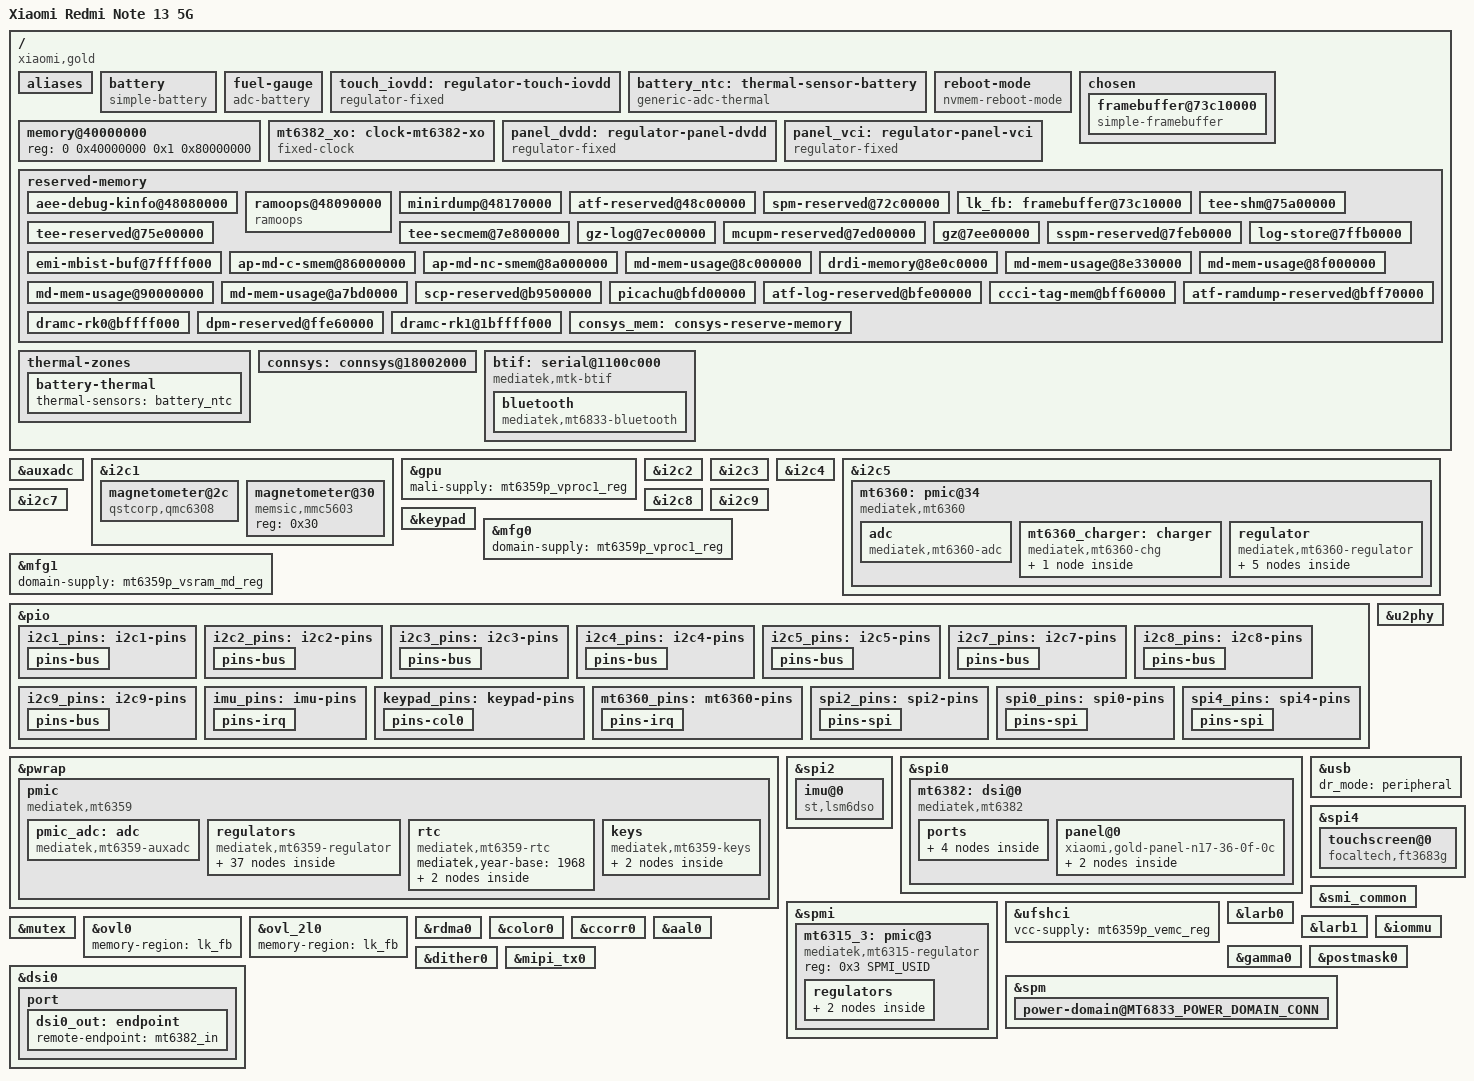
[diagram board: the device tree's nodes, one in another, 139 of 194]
// SPDX-License-Identifier: (GPL-2.0-only OR MIT)
/*
 * Xiaomi Redmi Note 13 5G (gold)
 */

/dts-v1/;
#include <dt-bindings/gpio/gpio.h>
#include <dt-bindings/iio/adc/mediatek,mt6359-auxadc.h>
#include <dt-bindings/input/input.h>
#include <dt-bindings/interrupt-controller/irq.h>
#include <dt-bindings/pinctrl/mt6833-pinfunc.h>
#include <dt-bindings/regulator/mediatek,mt6360-regulator.h>
#include <dt-bindings/spmi/spmi.h>
#include "mt6833.dtsi"

/ {
	model = "Xiaomi Redmi Note 13 5G";
	compatible = "xiaomi,gold", "mediatek,mt6833";
	chassis-type = "handset";

	aliases {
		i2c1 = &i2c1;
		i2c2 = &i2c2;
		i2c3 = &i2c3;
		i2c4 = &i2c4;
		i2c5 = &i2c5;
		i2c7 = &i2c7;
		i2c8 = &i2c8;
		i2c9 = &i2c9;
	};

	/*
	 * As the stock kernel charges it through the MT6360 alone at 15-47 C, before the cycle
	 * count lowers the voltage: up to 4.46 V (4.47-4.48 V only below 15 C), at 2 A (2.05 A
	 * for wall chargers), ending at 250 mA.
	 */
	battery: battery {
		compatible = "simple-battery";
		constant-charge-voltage-max-microvolt = <4460000>;
		constant-charge-current-max-microamp = <2000000>;
		charge-term-current-microamp = <250000>;

		/*
		 * The stock JEITA steps for chargers other than PPS, in whole degrees: no
		 * charging at -10 C and below or at 58 C and above; 490 mA at -9 to 0 C (980 mA
		 * at 1 to 5 C: taken as 490 mA here, which the MT6360 sets as 400 mA); 2.45-3.6 A
		 * at 6-47 C, more than the MT6360 alone gives; at 48-57 C only up to 4.1 V.
		 */
		operating-range-celsius = <(-9) 57>;
		alert-celsius = <6 47>;
		alert-low-temp-charge-current-microamp = <490000>;
		alert-high-temp-charge-voltage-microvolt = <4100000>;

		/*
		 * The stock gauge's profile for the first of the two cells it knows (battery0, the
		 * one it takes when the authentication chip names neither) at 25 C: OCV by depth of
		 * discharge down to 2.88 V (5104 mAh), and the median of its discharge resistance
		 * from 10 to 90 %. The stock kernel reports a design capacity of 5000 mAh.
		 */
		charge-full-design-microamp-hours = <5000000>;
		factory-internal-resistance-micro-ohms = <54000>;
		ocv-capacity-celsius = <25>;
		ocv-capacity-table-0 = <4445000 100>, <4379000 95>, <4321000 90>, <4260000 85>,
				       <4196000 80>, <4134000 75>, <4077000 70>, <4024000 65>,
				       <3976000 60>, <3919000 55>, <3871000 50>, <3842000 45>,
				       <3818000 40>, <3800000 35>, <3784000 30>, <3761000 25>,
				       <3740000 20>, <3712000 15>, <3687000 10>, <3623000 5>,
				       <3569000 4>, <3498000 3>, <3397000 2>, <3232000 1>,
				       <2880000 0>;
	};

	/*
	 * The MT6359P measures the battery voltage, and its fuel gauge the current through the
	 * 5 mOhm sense resistor, positive while charging.
	 */
	fuel-gauge {
		compatible = "adc-battery";
		io-channels = <&pmic_adc MT6359_AUXADC_BATADC>,
			      <&pmic_adc MT6359_AUXADC_IBAT>,
			      <&battery_ntc>;
		io-channel-names = "voltage", "current", "temperature";
		monitored-battery = <&battery>;
		power-supplies = <&mt6360_charger>;
	};

	/* the touchscreen's I/O supply, switched by a GPIO; on at handover */
	touch_iovdd: regulator-touch-iovdd {
		compatible = "regulator-fixed";
		regulator-name = "touch_iovdd";
		regulator-min-microvolt = <1800000>;
		regulator-max-microvolt = <1800000>;
		gpio = <&pio 138 GPIO_ACTIVE_HIGH>;
		enable-active-high;
		regulator-boot-on;
	};

	/*
	 * The battery's NTC thermistor, a Murata NCP15XH103 (10 kOhm, B 3380 K) as the stock
	 * kernel's table has it, on the MT6359P's BATON pin, pulled up to VBIF28 (2.8 V) through
	 * 24 kOhm. Its voltage in mV, 2800 * R / (R + 24000), by temperature in millicelsius.
	 */
	battery_ntc: thermal-sensor-battery {
		compatible = "generic-adc-thermal";
		#thermal-sensor-cells = <0>;
		#io-channel-cells = <0>;
		io-channels = <&pmic_adc MT6359_AUXADC_BAT_TEMP>;
		io-channel-names = "sensor-channel";
		temperature-lookup-table = <
			(-40000) 2494  (-35000) 2410  (-30000) 2311  (-25000) 2198
			(-20000) 2071  (-15000) 1935  (-10000) 1790   (-5000) 1639
			      0  1488     5000  1340    10000  1197    15000  1062
			  20000   938    25000   824    30000   720    35000   629
			  40000   548    45000   476    50000   414    55000   359
			  60000   312    65000   272    70000   238    75000   208
			  80000   182    85000   160    90000   141    95000   124
			 100000   109   105000    97   110000    86   115000    76
			 120000    68   125000    61
		>;
	};

	reboot-mode {
		compatible = "nvmem-reboot-mode";
		nvmem-cells = <&rtc_fastboot>;
		nvmem-cell-names = "reboot-mode";
		mode-bootloader = <1>;
	};

	chosen {
		#address-cells = <2>;
		#size-cells = <2>;
		ranges;

		bootargs = "console=tty0 loglevel=7 panic=10 clk_ignore_unused";

		/* The bootloader leaves the panel lit, scanning out this buffer */
		framebuffer@73c10000 {
			compatible = "simple-framebuffer";
			reg = <0 0x73c10000 0 (4352 * 2400)>;
			width = <1080>;
			height = <2400>;
			stride = <4352>;
			format = "a8r8g8b8";
		};
	};

	memory@40000000 {
		device_type = "memory";
		reg = <0 0x40000000 0x1 0x80000000>;
	};

	/*
	 * The MT6359P clock buffer output (XO_NFC) the MT6382 runs from, and
	 * passes on to an NFC controller as its own clock output. The
	 * bootloader turns it on; there is no clock buffer driver yet, so it is
	 * described as always running.
	 */
	mt6382_xo: clock-mt6382-xo {
		compatible = "fixed-clock";
		#clock-cells = <0>;
		clock-frequency = <26000000>;
		clock-output-names = "xo_nfc";
	};

	/* The panel supplies behind GPIO131 and GPIO137, left on by the bootloader */
	panel_dvdd: regulator-panel-dvdd {
		compatible = "regulator-fixed";
		regulator-name = "panel_dvdd";
		gpio = <&pio 131 GPIO_ACTIVE_HIGH>;
		enable-active-high;
		regulator-boot-on;
		startup-delay-us = <11000>;
	};

	/* never switched off by the stock kernel either */
	panel_vci: regulator-panel-vci {
		compatible = "regulator-fixed";
		regulator-name = "panel_vci";
		gpio = <&pio 137 GPIO_ACTIVE_HIGH>;
		enable-active-high;
		regulator-boot-on;
		regulator-always-on;
	};

	/*
	 * The regions the bootloader reserves for the firmware it starts (ATF, TEE, GenieZone, the
	 * SSPM, MCUPM and SCP coprocessors, the modem) and for itself, as it reports them.
	 */
	reserved-memory {
		#address-cells = <2>;
		#size-cells = <2>;
		ranges;

		aee-debug-kinfo@48080000 {
			reg = <0x0 0x48080000 0 0x10000>;
			no-map;
		};

		ramoops@48090000 {
			compatible = "ramoops";
			reg = <0x0 0x48090000 0 0xe0000>;
			console-size = <0x40000>;
			pmsg-size = <0x80000>;
			no-map;
		};

		minirdump@48170000 {
			reg = <0x0 0x48170000 0 0x10000>;
			no-map;
		};

		atf-reserved@48c00000 {
			reg = <0x0 0x48c00000 0 0x200000>;
			no-map;
		};

		spm-reserved@72c00000 {
			reg = <0x0 0x72c00000 0 0x10000>;
			no-map;
		};

		/*
		 * The bootloader's framebuffer, which the display keeps scanning
		 * out when its driver takes over: 1:1 in the display's IOMMU
		 * domain, so that it stays valid when the larb ports switch from
		 * physical addresses to the M4U.
		 */
		lk_fb: framebuffer@73c10000 {
			reg = <0x0 0x73c10000 0 0x1df0000>;
			iommu-addresses = <&ovl0 0x0 0x73c10000 0x0 0x1df0000>,
					  <&ovl_2l0 0x0 0x73c10000 0x0 0x1df0000>;
			no-map;
		};

		tee-shm@75a00000 {
			reg = <0x0 0x75a00000 0 0x400000>;
			no-map;
		};

		tee-reserved@75e00000 {
			reg = <0x0 0x75e00000 0 0x8a00000>;
			no-map;
		};

		tee-secmem@7e800000 {
			reg = <0x0 0x7e800000 0 0x400000>;
			no-map;
		};

		gz-log@7ec00000 {
			reg = <0x0 0x7ec00000 0 0x41000>;
			no-map;
		};

		mcupm-reserved@7ed00000 {
			reg = <0x0 0x7ed00000 0 0x100000>;
			no-map;
		};

		gz@7ee00000 {
			reg = <0x0 0x7ee00000 0 0x1000000>;
			no-map;
		};

		sspm-reserved@7feb0000 {
			reg = <0x0 0x7feb0000 0 0x100000>;
			no-map;
		};

		log-store@7ffb0000 {
			reg = <0x0 0x7ffb0000 0 0x40000>;
			no-map;
		};

		emi-mbist-buf@7ffff000 {
			reg = <0x0 0x7ffff000 0 0x1000>;
			no-map;
		};

		ap-md-c-smem@86000000 {
			reg = <0x0 0x86000000 0 0x2960000>;
			no-map;
		};

		ap-md-nc-smem@8a000000 {
			reg = <0x0 0x8a000000 0 0x1b0000>;
			no-map;
		};

		md-mem-usage@8c000000 {
			reg = <0x0 0x8c000000 0 0x20c0000>;
			no-map;
		};

		drdi-memory@8e0c0000 {
			reg = <0x0 0x8e0c0000 0 0x270000>;
			no-map;
		};

		md-mem-usage@8e330000 {
			reg = <0x0 0x8e330000 0 0x10000>;
			no-map;
		};

		md-mem-usage@8f000000 {
			reg = <0x0 0x8f000000 0 0xf0000>;
			no-map;
		};

		md-mem-usage@90000000 {
			reg = <0x0 0x90000000 0 0x7210000>;
			no-map;
		};

		md-mem-usage@a7bd0000 {
			reg = <0x0 0xa7bd0000 0 0x1730000>;
			no-map;
		};

		scp-reserved@b9500000 {
			reg = <0x0 0xb9500000 0 0x400000>;
			no-map;
		};

		picachu@bfd00000 {
			reg = <0x0 0xbfd00000 0 0x80000>;
			no-map;
		};

		atf-log-reserved@bfe00000 {
			reg = <0x0 0xbfe00000 0 0x40000>;
			no-map;
		};

		ccci-tag-mem@bff60000 {
			reg = <0x0 0xbff60000 0 0x10000>;
			no-map;
		};

		atf-ramdump-reserved@bff70000 {
			reg = <0x0 0xbff70000 0 0x80000>;
			no-map;
		};

		dramc-rk0@bffff000 {
			reg = <0x0 0xbffff000 0 0x1000>;
			no-map;
		};

		dpm-reserved@ffe60000 {
			reg = <0x0 0xffe60000 0 0x190000>;
			no-map;
		};

		dramc-rk1@1bffff000 {
			reg = <0x1 0xbffff000 0 0x1000>;
			no-map;
		};
	};

	thermal-zones {
		battery-thermal {
			thermal-sensors = <&battery_ntc>;
		};
	};
};

/*
 * Channels 0 to 3: NTC thermistors (100 kOhm, pulled up to 1.8 V through 100 kOhm), 0 the one
 * the stock CPU zone reads, 2 also the one the modem is handed; 5: the board revision divider
 */
&auxadc {
	status = "okay";
};

/*
 * The stock software leaves this bus to the SCP, which runs the sensors; Linux does not start
 * the SCP, so the AP's controller takes the pins. Also here: the ambient light and proximity
 * sensor (AMS TCS3701) at 0x39.
 */
&i2c1 {
	clock-frequency = <400000>;
	pinctrl-names = "default";
	pinctrl-0 = <&i2c1_pins>;
	status = "okay";

	/* the magnetometer: the stock SCP firmware knows a QMC6308 and an MMC5603 */
	magnetometer@2c {
		compatible = "qstcorp,qmc6308";
		reg = <0x2c>;
		vdd-supply = <&mt6359p_vio18_reg>;
		mount-matrix = "0", "-1", "0",
			       "1", "0", "0",
			       "0", "0", "1";
	};

	magnetometer@30 {
		compatible = "memsic,mmc5603";
		reg = <0x30>;
	};
};

&gpu {
	mali-supply = <&mt6359p_vproc1_reg>;
	status = "okay";
};

&i2c2 {
	/* The main rear camera's sensor, EEPROM and focus motors */
	clock-frequency = <1000000>;
	pinctrl-names = "default";
	pinctrl-0 = <&i2c2_pins>;
	status = "okay";
};

&i2c3 {
	/* The NFC controller (ST21NFC) */
	clock-frequency = <400000>;
	pinctrl-names = "default";
	pinctrl-0 = <&i2c3_pins>;
	status = "okay";
};

&i2c4 {
	/* The front camera's sensor and EEPROM, a focus motor */
	clock-frequency = <400000>;
	pinctrl-names = "default";
	pinctrl-0 = <&i2c4_pins>;
	status = "okay";
};

&i2c5 {
	/* The MT6360 PMIC: in high-speed mode, push-pull, as the stock kernel drives it */
	clock-frequency = <3400000>;
	mediatek,use-push-pull;
	pinctrl-names = "default";
	pinctrl-0 = <&i2c5_pins>;
	status = "okay";

	mt6360: pmic@34 {
		compatible = "mediatek,mt6360";
		reg = <0x34>;
		interrupts-extended = <&pio 10 IRQ_TYPE_LEVEL_LOW>;
		interrupt-names = "IRQB";
		interrupt-controller;
		#interrupt-cells = <1>;
		pinctrl-names = "default";
		pinctrl-0 = <&mt6360_pins>;
		wakeup-source;

		adc {
			compatible = "mediatek,mt6360-adc";
			#io-channel-cells = <1>;
		};

		mt6360_charger: charger {
			compatible = "mediatek,mt6360-chg";
			io-channels = <&battery_ntc>;
			io-channel-names = "battery-temp";
			monitored-battery = <&battery>;
			richtek,vinovp-microvolt = <14500000>;

			otg_vbus_reg: usb-otg-vbus-regulator {
				regulator-name = "usb-otg-vbus";
				regulator-min-microvolt = <4425000>;
				regulator-max-microvolt = <5825000>;
			};
		};

		/*
		 * As gold's stock device tree constrains them (LDO2 as its overlay does). Left out
		 * until their consumers are in, so that Linux does not switch them: LDO1 (the
		 * fingerprint sensor's), LDO3 and LDO5 (the microSD card's).
		 */
		regulator {
			compatible = "mediatek,mt6360-regulator";

			mt6360_buck1_reg: buck1 {
				regulator-name = "mt6360,buck1";
				regulator-min-microvolt = <300000>;
				regulator-max-microvolt = <1300000>;
				regulator-allowed-modes = <MT6360_OPMODE_NORMAL
							   MT6360_OPMODE_LP
							   MT6360_OPMODE_ULP>;
				regulator-always-on;
			};

			mt6360_buck2_reg: buck2 {
				regulator-name = "mt6360,buck2";
				regulator-min-microvolt = <300000>;
				regulator-max-microvolt = <1300000>;
				regulator-allowed-modes = <MT6360_OPMODE_NORMAL
							   MT6360_OPMODE_LP
							   MT6360_OPMODE_ULP>;
				regulator-always-on;
			};

			/* the touchscreen's analog supply (VTP) */
			mt6360_ldo2_reg: ldo2 {
				regulator-name = "vtp";
				regulator-min-microvolt = <3300000>;
				regulator-max-microvolt = <3300000>;
			};

			mt6360_ldo6_reg: ldo6 {
				regulator-name = "mt6360,ldo6";
				regulator-min-microvolt = <500000>;
				regulator-max-microvolt = <2100000>;
				regulator-allowed-modes = <MT6360_OPMODE_NORMAL
							   MT6360_OPMODE_LP>;
				regulator-always-on;
			};

			mt6360_ldo7_reg: ldo7 {
				regulator-name = "mt6360,ldo7";
				regulator-min-microvolt = <500000>;
				regulator-max-microvolt = <2100000>;
				regulator-allowed-modes = <MT6360_OPMODE_NORMAL
							   MT6360_OPMODE_LP>;
				regulator-always-on;
			};
		};
	};
};

&i2c7 {
	/* The speaker amplifier (SIA81xx), the cameras' LDOs, the LN8000 charge pump */
	clock-frequency = <400000>;
	pinctrl-names = "default";
	pinctrl-0 = <&i2c7_pins>;
	status = "okay";
};

&i2c8 {
	/* The second rear camera's sensor and EEPROM */
	clock-frequency = <400000>;
	pinctrl-names = "default";
	pinctrl-0 = <&i2c8_pins>;
	status = "okay";
};

&i2c9 {
	/* The third rear camera's sensor and EEPROM */
	clock-frequency = <400000>;
	pinctrl-names = "default";
	pinctrl-0 = <&i2c9_pins>;
	status = "okay";
};

&keypad {
	pinctrl-names = "default";
	pinctrl-0 = <&keypad_pins>;
	/* the scan the bootloader leaves set up: three rows, three columns */
	keypad,num-rows = <3>;
	keypad,num-columns = <3>;
	debounce-delay-ms = <32>;
	linux,keymap = <MATRIX_KEY(0, 0, KEY_VOLUMEDOWN)>;
	status = "okay";
};

&mfg0 {
	domain-supply = <&mt6359p_vproc1_reg>;
};

&mfg1 {
	domain-supply = <&mt6359p_vsram_md_reg>;
};

&pio {
	i2c1_pins: i2c1-pins {
		pins-bus {
			pinmux = <PINMUX_GPIO99__FUNC_SCL1>,
				 <PINMUX_GPIO100__FUNC_SDA1>;
		};
	};

	i2c2_pins: i2c2-pins {
		pins-bus {
			pinmux = <PINMUX_GPIO101__FUNC_SCL2>,
				 <PINMUX_GPIO102__FUNC_SDA2>;
		};
	};

	i2c3_pins: i2c3-pins {
		pins-bus {
			pinmux = <PINMUX_GPIO103__FUNC_SCL3>,
				 <PINMUX_GPIO104__FUNC_SDA3>;
		};
	};

	i2c4_pins: i2c4-pins {
		pins-bus {
			pinmux = <PINMUX_GPIO105__FUNC_SCL4>,
				 <PINMUX_GPIO106__FUNC_SDA4>;
		};
	};

	i2c5_pins: i2c5-pins {
		pins-bus {
			pinmux = <PINMUX_GPIO107__FUNC_SCL5>,
				 <PINMUX_GPIO108__FUNC_SDA5>;
		};
	};

	i2c7_pins: i2c7-pins {
		pins-bus {
			pinmux = <PINMUX_GPIO111__FUNC_SCL7>,
				 <PINMUX_GPIO112__FUNC_SDA7>;
		};
	};

	i2c8_pins: i2c8-pins {
		pins-bus {
			pinmux = <PINMUX_GPIO113__FUNC_SCL8>,
				 <PINMUX_GPIO114__FUNC_SDA8>;
		};
	};

	i2c9_pins: i2c9-pins {
		pins-bus {
			pinmux = <PINMUX_GPIO141__FUNC_SCL9>,
				 <PINMUX_GPIO142__FUNC_SDA9>;
		};
	};

	imu_pins: imu-pins {
		pins-irq {
			pinmux = <PINMUX_GPIO3__FUNC_GPIO3>;
			bias-pull-down;
		};
	};

	keypad_pins: keypad-pins {
		pins-col0 {
			pinmux = <PINMUX_GPIO79__FUNC_KPCOL0>;
			bias-pull-up = <MTK_PUPD_SET_R1R0_10>;
			input-schmitt-enable;
		};
	};

	mt6360_pins: mt6360-pins {
		pins-irq {
			pinmux = <PINMUX_GPIO10__FUNC_GPIO10>;
			bias-pull-up;
		};
	};

	spi2_pins: spi2-pins {
		pins-spi {
			pinmux = <PINMUX_GPIO31__FUNC_SPI2_CLK>,
				 <PINMUX_GPIO32__FUNC_SPI2_CSB>,
				 <PINMUX_GPIO33__FUNC_SPI2_MO>,
				 <PINMUX_GPIO34__FUNC_SPI2_MI>;
		};
	};

	spi0_pins: spi0-pins {
		pins-spi {
			pinmux = <PINMUX_GPIO23__FUNC_SPI0_CLK>,
				 <PINMUX_GPIO24__FUNC_SPI0_CSB>,
				 <PINMUX_GPIO25__FUNC_SPI0_MO>,
				 <PINMUX_GPIO26__FUNC_SPI0_MI>;
			drive-strength = <8>;
		};
	};
};

&pwrap {
	pmic: pmic {
		compatible = "mediatek,mt6359";
		interrupts-extended = <&pio 118 IRQ_TYPE_LEVEL_HIGH>;
		interrupt-controller;
		#interrupt-cells = <2>;

		pmic_adc: adc {
			compatible = "mediatek,mt6359-auxadc";
			#io-channel-cells = <1>;
		};

		/*
		 * As gold's stock device tree constrains them (with its dtbo: VIO28 is 3.3 V), without
		 * its ramp settings. Left out, so that Linux does not touch them: the ones on at handover
		 * but not always-on there (Linux turns unused ones it may switch off), until a consumer
		 * of theirs is in, VCN33's Bluetooth and Wi-Fi enables (their state does not read back),
		 * and the SIM, connectivity and SSHUB ones the stock tree leaves out.
		 */
		regulators {
			compatible = "mediatek,mt6359-regulator";

			mt6359p_vs1_reg: buck_vs1 {
				regulator-name = "vs1";
				regulator-min-microvolt = <800000>;
				regulator-max-microvolt = <2200000>;
				regulator-always-on;
			};

			mt6359p_vgpu11_reg: buck_vgpu11 {
				regulator-name = "vgpu11";
				regulator-min-microvolt = <400000>;
				regulator-max-microvolt = <1193750>;
				regulator-always-on;
			};

			mt6359p_vmodem_reg: buck_vmodem {
				regulator-name = "vmodem";
				regulator-min-microvolt = <400000>;
				regulator-max-microvolt = <1100000>;
			};

			mt6359p_vpu_reg: buck_vpu {
				regulator-name = "vpu";
				regulator-min-microvolt = <400000>;
				regulator-max-microvolt = <1193750>;
				regulator-always-on;
			};

			mt6359p_vcore_reg: buck_vcore {
				regulator-name = "vcore";
				regulator-min-microvolt = <506250>;
				regulator-max-microvolt = <1300000>;
				regulator-always-on;
			};

			mt6359p_vs2_reg: buck_vs2 {
				regulator-name = "vs2";
				regulator-min-microvolt = <800000>;
				regulator-max-microvolt = <1600000>;
				regulator-always-on;
			};

			mt6359p_vpa_reg: buck_vpa {
				regulator-name = "vpa";
				regulator-min-microvolt = <500000>;
				regulator-max-microvolt = <3650000>;
			};

			mt6359p_vproc2_reg: buck_vproc2 {
				regulator-name = "vproc2";
				regulator-min-microvolt = <400000>;
				regulator-max-microvolt = <1193750>;
				regulator-always-on;
			};

			/*
			 * The GPU's, as for the stock gpufreq; at most its SRAM's voltage.
			 * It settles as long as the stock kernel waits for it: the stock
			 * ramp (7.5 mV/us) and then gpufreq's 10 mV/us plus 9 us, 50 us
			 * across this range.
			 */
			mt6359p_vproc1_reg: buck_vproc1 {
				regulator-name = "vproc1";
				regulator-min-microvolt = <575000>;
				regulator-max-microvolt = <750000>;
				regulator-enable-ramp-delay = <200>;
				regulator-settling-time-us = <50>;
			};

			mt6359p_vibr_reg: ldo_vibr {
				regulator-name = "vibr";
				regulator-min-microvolt = <1200000>;
				regulator-max-microvolt = <3300000>;
			};

			/* Pulls the battery thermistor up */
			mt6359p_vbif28_reg: ldo_vbif28 {
				regulator-name = "vbif28";
				regulator-min-microvolt = <2800000>;
				regulator-max-microvolt = <2800000>;
				regulator-always-on;
			};

			mt6359p_vrf12_reg: ldo_vrf12 {
				regulator-name = "vrf12";
				regulator-min-microvolt = <1100000>;
				regulator-max-microvolt = <1300000>;
				regulator-always-on;
			};

			mt6359p_vusb_reg: ldo_vusb {
				regulator-name = "vusb";
				regulator-min-microvolt = <3000000>;
				regulator-max-microvolt = <3000000>;
				regulator-always-on;
			};

			mt6359p_vsram_proc2_reg: ldo_vsram_proc2 {
				regulator-name = "vsram_proc2";
				regulator-min-microvolt = <500000>;
				regulator-max-microvolt = <1293750>;
				regulator-always-on;
			};

			mt6359p_vio18_reg: ldo_vio18 {
				regulator-name = "vio18";
				regulator-min-microvolt = <1700000>;
				regulator-max-microvolt = <1900000>;
				regulator-always-on;
			};

			mt6359p_vcamio_reg: ldo_vcamio {
				regulator-name = "vcamio";
				regulator-min-microvolt = <1700000>;
				regulator-max-microvolt = <1900000>;
			};

			mt6359p_vcn18_reg: ldo_vcn18 {
				regulator-name = "vcn18";
				regulator-min-microvolt = <1800000>;
				regulator-max-microvolt = <1800000>;
			};

			mt6359p_vfe28_reg: ldo_vfe28 {
				regulator-name = "vfe28";
				regulator-min-microvolt = <2800000>;
				regulator-max-microvolt = <2800000>;
			};

			mt6359p_vcn13_reg: ldo_vcn13 {
				regulator-name = "vcn13";
				regulator-min-microvolt = <900000>;
				regulator-max-microvolt = <1300000>;
			};

			mt6359p_vaux18_reg: ldo_vaux18 {
				regulator-name = "vaux18";
				regulator-min-microvolt = <1800000>;
				regulator-max-microvolt = <1800000>;
				regulator-always-on;
			};

			mt6359p_vsram_others_reg: ldo_vsram_others {
				regulator-name = "vsram_others";
				regulator-min-microvolt = <500000>;
				regulator-max-microvolt = <1293750>;
				regulator-always-on;
			};

			mt6359p_vefuse_reg: ldo_vefuse {
				regulator-name = "vefuse";
				regulator-min-microvolt = <1700000>;
				regulator-max-microvolt = <2000000>;
			};

			mt6359p_vxo22_reg: ldo_vxo22 {
				regulator-name = "vxo22";
				regulator-min-microvolt = <1800000>;
				regulator-max-microvolt = <2200000>;
				regulator-always-on;
			};

			mt6359p_vrfck_reg: ldo_vrfck_1 {
				regulator-name = "vrfck";
				regulator-min-microvolt = <1240000>;
				regulator-max-microvolt = <1600000>;
			};

			mt6359p_vio28_reg: ldo_vio28 {
				regulator-name = "vio28";
				regulator-min-microvolt = <3300000>;
				regulator-max-microvolt = <3300000>;
				regulator-always-on;
			};

			mt6359p_vemc_reg: ldo_vemc_1 {
				regulator-name = "vemc";
				regulator-min-microvolt = <2500000>;
				regulator-max-microvolt = <3300000>;
				regulator-always-on;
			};

			mt6359p_va12_reg: ldo_va12 {
				regulator-name = "va12";
				regulator-min-microvolt = <1200000>;
				regulator-max-microvolt = <1300000>;
				regulator-always-on;
			};

			mt6359p_va09_reg: ldo_va09 {
				regulator-name = "va09";
				regulator-min-microvolt = <800000>;
				regulator-max-microvolt = <1200000>;
				regulator-always-on;
			};

			mt6359p_vrf18_reg: ldo_vrf18 {
				regulator-name = "vrf18";
				regulator-min-microvolt = <1700000>;
				regulator-max-microvolt = <1810000>;
			};

			/*
			 * The GPU's SRAM, as for the stock gpufreq, which keeps it at
			 * 0.75 V for any GPU voltage up to 0.75 V
			 */
			mt6359p_vsram_md_reg: ldo_vsram_md {
				regulator-name = "vsram_md";
				regulator-min-microvolt = <750000>;
				regulator-max-microvolt = <750000>;
				regulator-enable-ramp-delay = <240>;
			};

			mt6359p_vufs_reg: ldo_vufs {
				regulator-name = "vufs";
				regulator-min-microvolt = <1700000>;
				regulator-max-microvolt = <1900000>;
				regulator-always-on;
			};

			mt6359p_vm18_reg: ldo_vm18 {
				regulator-name = "vm18";
				regulator-min-microvolt = <1700000>;
				regulator-max-microvolt = <1900000>;
				regulator-always-on;
			};

			mt6359p_vbbck_reg: ldo_vbbck {
				regulator-name = "vbbck";
				regulator-min-microvolt = <1100000>;
				regulator-max-microvolt = <1200000>;
			};

			mt6359p_vsram_proc1_reg: ldo_vsram_proc1 {
				regulator-name = "vsram_proc1";
				regulator-min-microvolt = <500000>;
				regulator-max-microvolt = <1293750>;
				regulator-always-on;
			};

			mt6359p_vsram_others_sshub_reg: ldo_vsram_others_sshub {
				regulator-name = "vsram_others_sshub";
				regulator-min-microvolt = <500000>;
				regulator-max-microvolt = <1193750>;
			};
		};

		rtc {
			compatible = "mediatek,mt6359-rtc", "mediatek,mt6358-rtc";
			/* as gold's preloader, LK and stock kernel count the years */
			mediatek,year-base = <1968>;

			nvmem-layout {
				compatible = "fixed-layout";
				#address-cells = <1>;
				#size-cells = <1>;

				/* PDN1 bit 13 (bit 5 of its high byte): LK enters fastboot and clears it */
				rtc_fastboot: fastboot@5 {
					reg = <5 1>;
					bits = <5 1>;
				};
			};
		};

		keys {
			compatible = "mediatek,mt6359-keys";
			/* Holding power alone resets the phone, as under the stock kernel */
			mediatek,long-press-mode = <1>;
			power-off-time-sec = <0>;

			power-key {
				linux,keycodes = <KEY_POWER>;
				wakeup-source;
			};

			home-key {
				linux,keycodes = <KEY_VOLUMEUP>;
			};
		};
	};
};

/* The stock software leaves this bus to the SCP, as SCP_SPI2; see i2c1 */
&spi2 {
	pinctrl-names = "default";
	pinctrl-0 = <&spi2_pins>;
	mediatek,pad-select = <0>;
	status = "okay";

	/* an ST LSM6DSO here; the stock SCP firmware also knows a Bosch BMI320 */
	imu@0 {
		compatible = "st,lsm6dso";
		reg = <0>;
		spi-max-frequency = <10000000>;
		interrupts-extended = <&pio 3 IRQ_TYPE_LEVEL_HIGH>;
		pinctrl-names = "default";
		pinctrl-0 = <&imu_pins>;
		vddio-supply = <&mt6359p_vio18_reg>;
		mount-matrix = "1", "0", "0",
			       "0", "-1", "0",
			       "0", "0", "-1";
	};
};

/* The MT6382 display bridge's configuration port */
&spi0 {
	pinctrl-names = "default";
	pinctrl-0 = <&spi0_pins>;
	mediatek,pad-select = <0>;
	status = "okay";

	/* The bridge between DSI0 and the panel, which sits behind it */
	mt6382: dsi@0 {
		compatible = "mediatek,mt6382";
		reg = <0>;
		spi-max-frequency = <55000000>;
		spi-lsb-first;
		clocks = <&mt6382_xo>;
		reset-gpios = <&pio 20 GPIO_ACTIVE_LOW>;
		#clock-cells = <0>;
		#address-cells = <1>;
		#size-cells = <0>;

		ports {
			#address-cells = <1>;
			#size-cells = <0>;

			port@0 {
				reg = <0>;

				mt6382_in: endpoint {
					remote-endpoint = <&dsi0_out>;
				};
			};

			port@1 {
				reg = <1>;

				mt6382_out: endpoint {
					remote-endpoint = <&panel_in>;
				};
			};
		};

		panel@0 {
			compatible = "xiaomi,gold-panel-n17-36-0f-0c";
			reg = <0>;
			vdd-supply = <&panel_dvdd>;
			vddio-supply = <&mt6359p_vio18_reg>;
			vci-supply = <&panel_vci>;
			reset-gpios = <&pio 86 GPIO_ACTIVE_LOW>;

			port {
				panel_in: endpoint {
					remote-endpoint = <&mt6382_out>;
				};
			};
		};
	};
};

&spmi {
	status = "okay";

	mt6315_3: pmic@3 {
		compatible = "mediatek,mt6315-regulator";
		reg = <0x3 SPMI_USID>;

		/*
		 * As gold's stock device tree constrains them, without its ramp settings and modes.
		 * Buck 3, which LK turns off and nothing uses, is left out so that Linux does not
		 * touch it.
		 */
		regulators {
			mt6315_3_vbuck1: vbuck1 {
				regulator-name = "3_vbuck1";
				regulator-min-microvolt = <300000>;
				regulator-max-microvolt = <1193750>;
				regulator-always-on;
			};

			mt6315_3_vbuck4: vbuck4 {
				regulator-name = "3_vbuck4";
				regulator-min-microvolt = <300000>;
				regulator-max-microvolt = <1193750>;
				regulator-always-on;
			};
		};
	};
};

&u2phy {
	status = "okay";
};

/* Device mode only until the Type-C port controller and its role switch are in */
&usb {
	dr_mode = "peripheral";
	status = "okay";
};

&ufshci {
	vcc-supply = <&mt6359p_vemc_reg>;
	status = "okay";
};

&pio {
	spi4_pins: spi4-pins {
		pins-spi {
			pinmux = <PINMUX_GPIO12__FUNC_SPI4_MI>,
				 <PINMUX_GPIO13__FUNC_SPI4_MO>,
				 <PINMUX_GPIO97__FUNC_SPI4_CLK>,
				 <PINMUX_GPIO98__FUNC_SPI4_CSB>;
		};
	};
};

/*
 * The touchscreen: an FT3683G here, a Goodix GT9916R in other units, on the one chip select. Its analog
 */
&spi4 {
	pinctrl-names = "default";
	pinctrl-0 = <&spi4_pins>;
	mediatek,pad-select = <0>;
	status = "okay";

	touchscreen@0 {
		compatible = "focaltech,ft3683g";
		reg = <0>;
		spi-max-frequency = <6000000>;
		interrupts-extended = <&pio 14 IRQ_TYPE_EDGE_FALLING>;
		reset-gpios = <&pio 15 GPIO_ACTIVE_LOW>;
		avdd-supply = <&mt6360_ldo2_reg>;
		iovdd-supply = <&touch_iovdd>;
		/* in sixteenths of a pixel */
		touchscreen-size-x = <17280>;
		touchscreen-size-y = <38400>;
	};
};

/*
 * The display path: OVL0 and OVL_2L0 through RDMA0 to DSI0, which drives the
 * MT6382, with its memory masters behind larb0 and larb1, the SMI and the M4U
 */
&smi_common {
	status = "okay";
};

&larb0 {
	status = "okay";
};

&larb1 {
	status = "okay";
};

&iommu {
	status = "okay";
};

&mutex {
	status = "okay";
};

&ovl0 {
	memory-region = <&lk_fb>;
	status = "okay";
};

&ovl_2l0 {
	memory-region = <&lk_fb>;
	status = "okay";
};

&rdma0 {
	status = "okay";
};

&color0 {
	status = "okay";
};

&ccorr0 {
	status = "okay";
};

&aal0 {
	status = "okay";
};

&gamma0 {
	status = "okay";
};

&postmask0 {
	status = "okay";
};

&dither0 {
	status = "okay";
};

&mipi_tx0 {
	status = "okay";
};

&dsi0 {
	status = "okay";

	port {
		dsi0_out: endpoint {
			remote-endpoint = <&mt6382_in>;
		};
	};
};

/* connsys Bluetooth (btmtkconn prototype) */
/ {
	reserved-memory {
		/* as the stock tree: allocated at boot, so the shim leaves it alone */
		consys_mem: consys-reserve-memory {
			no-map;
			size = <0 0x500000>;
			alignment = <0 0x1000000>;
			alloc-ranges = <0 0x40000000 0 0x80000000>;
		};
	};

	/* register ranges only, for btmtkconn */
	connsys: connsys@18002000 {
		reg = <0 0x18002000 0 0x1000>,
		      <0 0x10007000 0 0x100>,
		      <0 0x10001000 0 0x1000>,
		      <0 0x10006000 0 0x1000>,
		      <0 0x180b1000 0 0x1000>,
		      <0 0x180c1000 0 0x1000>,
		      <0 0x10003000 0 0x1000>,
		      <0 0x10005000 0 0x1000>,
		      <0 0x11ea0000 0 0x100>,
		      <0 0x1100c000 0 0x100>,
		      <0 0x1000f800 0 0x100>,
		      <0 0x18007000 0 0x1000>;
	};

	btif: serial@1100c000 {
		compatible = "mediatek,mtk-btif";
		reg = <0 0x1100c000 0 0x1000>;
		interrupts = <GIC_SPI 158 IRQ_TYPE_LEVEL_HIGH 0>;
		clocks = <&infracfg_ao CLK_IFRAO_BTIF>;
		clock-names = "main";
		reg-shift = <2>;
		reg-io-width = <4>;

		bluetooth {
			compatible = "mediatek,mt6833-bluetooth";
			mediatek,connsys = <&connsys>;
			power-domains = <&spm MT6833_POWER_DOMAIN_CONN>;
			clocks = <&infracfg_ao CLK_IFRAO_CCIF4_AP>;
			clock-names = "ccif";
			vcn18-supply = <&mt6359p_vcn18_reg>;
			vcn33-1-supply = <&mt6359p_vcn33_1_reg>;
			vcn33-2-supply = <&mt6359p_vcn33_2_reg>;
			memory-region = <&consys_mem>;
		};
	};
};

&spm {
	power-domain@MT6833_POWER_DOMAIN_CONN {
		reg = <MT6833_POWER_DOMAIN_CONN>;
		mediatek,infracfg = <&infracfg_ao>;
		#power-domain-cells = <0>;
	};
};

&pmic {
	regulators {
		mt6359p_vcn33_1_reg: ldo_vcn33_1 {
			regulator-name = "vcn33_1";
			regulator-min-microvolt = <2800000>;
			regulator-max-microvolt = <3500000>;
		};

		mt6359p_vcn33_2_reg: ldo_vcn33_2 {
			regulator-name = "vcn33_2";
			regulator-min-microvolt = <2800000>;
			regulator-max-microvolt = <3500000>;
		};
	};
};
